# cslr_cfg register map
Vendor: Texas Instruments
Peripheral module from a debugger description file (folder TCI6484_C6457).
Registers are 32-bit, access not given, reset 0x0 unless marked. A register's access mark holds for its fields unless they carry their own. Offsets are as the file gives them; lines under a group give offsets from that group; [hi:lo] are bit positions; {n}, {i} and the like mark numbered series; 'fields as' and 'values as' point back to an identical list; <NAME> marks a mode.

## CFG — Memory Protection for Configuration space
0x00 MPFAR rw — Config Memory Protection Fault Address Reg
  [31:0] ADDR — Config Fault Address
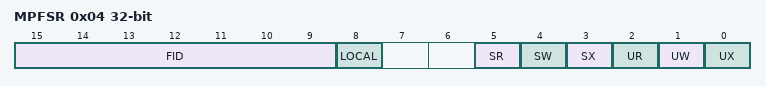
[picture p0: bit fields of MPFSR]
0x04 MPFSR — Config Memory Protection Fault Status Reg
  [15:9] FID ro — Bit 6:0 of faulting requestor. If ID is narrower than 7 bits, the remaining bits return 0. If ID is wider than 7 bits, the additional bits get truncated. FID = 0 if LOCAL = 1.
  [8] LOCAL ro — 0 - Normal operation. 1- Access was a "LOCAL" access.
  [5] SR ro — When set, indicates a Superviser read access type
  [4] SW ro — When set, indicates a Superviser write access type
  [3] SX ro — When set, indicates a Superviser execute access type
  [2] UR ro — When set, indicates a User read access type
  [1] UW ro — When set, indicates a User write access type
  [0] UX ro — When set, indicates a User execute access type
0x08 MPFCR — Config Memory Fault Clear Register
  [0] MPFCLR wo — Set to clear fault
    1=CLEAR (Clears Fault)
